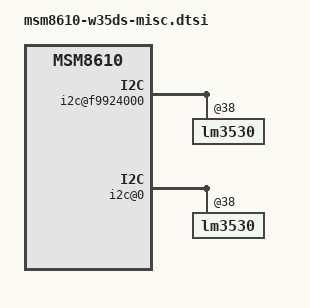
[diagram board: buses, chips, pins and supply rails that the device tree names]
/* Copyright (c) 2012, Code Aurora Forum. All rights reserved.
 *
 * This program is free software; you can redistribute it and/or modify
 * it under the terms of the GNU General Public License version 2 and
 * only version 2 as published by the Free Software Foundation.
 *
 * This program is distributed in the hope that it will be useful,
 * but WITHOUT ANY WARRANTY; without even the implied warranty of
 * MERCHANTABILITY or FITNESS FOR A PARTICULAR PURPOSE.  See the
 * GNU General Public License for more details.
 */

&soc {
	earjack-debugger {
		status = "disable";
	};

	i2c@f9924000 {
		rt8542@39 {
			status = "disable";
		};
        	lm3530@38 {
            		status = "ok";
            		revision = "rev_0";
        	};
		lp5521@32 {
			status = "disable";
			revision = "rev_0";
		};
	};

    i2c@0 {
        lm3530@38 {
            status = "ok";
            revision = "rev_a...";
            lm3530,max_current = <0x17>;
            lm3530,blmap = <
                0x01 0x01 0x01 0x01 0x01 0x01 0x01 0x01 0x01 0x01 /*09*/
                0x01 0x01 0x01 0x01 0x01 0x01 0x01 0x01 0x01 0x01 /*19*/
                0x01 0x01 0x01 0x01 0x01 0x01 0x02 0x02 0x02 0x02 /*29*/
                0x02 0x02 0x02 0x02 0x02 0x02 0x02 0x02 0x02 0x03 /*39*/
                0x03 0x03 0x03 0x03 0x03 0x03 0x03 0x03 0x03 0x03 /*49*/
                0x03 0x03 0x04 0x04 0x04 0x04 0x04 0x04 0x04 0x05 /*59*/
                0x05 0x05 0x05 0x05 0x05 0x05 0x05 0x06 0x06 0x06 /*69*/
                0x06 0x07 0x07 0x07 0x07 0x08 0x08 0x08 0x08 0x09 /*79*/
                0x09 0x09 0x09 0x0A 0x0A 0x0A 0x0B 0x0B 0x0B 0x0B /*89*/
                0x0B 0x0C 0x0C 0x0C 0x0C 0x0C 0x0D 0x0D 0x0D 0x0E /*99*/
                0x0E 0x0F 0x0F 0x10 0x10 0x10 0x11 0x11 0x12 0x12 /*109*/
                0x12 0x12 0x13 0x13 0x13 0x14 0x14 0x15 0x15 0x15 /*119*/
                0x16 0x16 0x16 0x17 0x17 0x18 0x18 0x19 0x19 0x1A /*129*/
                0x1B 0x1B 0x1C 0x1C 0x1C 0x1D 0x1D 0x1D 0x1D 0x1E /*139*/
                0x1E 0x1F 0x1F 0x1F 0x20 0x20 0x21 0x21 0x22 0x22 /*149*/
                0x22 0x22 0x23 0x23 0x24 0x24 0x25 0x26 0x26 0x26 /*159*/
                0x26 0x27 0x27 0x27 0x28 0x28 0x29 0x2A 0x2B 0x2B /*169*/
                0x2C 0x2D 0x2F 0x2F 0x30 0x31 0x31 0x32 0x33 0x34 /*179*/
                0x35 0x37 0x38 0x38 0x38 0x3A 0x3B 0x3C 0x3D 0x3E /*189*/
                0x3E 0x3F 0x40 0x41 0x41 0x41 0x42 0x43 0x43 0x44 /*199*/
                0x45 0x46 0x47 0x48 0x49 0x4B 0x4B 0x4B 0x4C 0x4D /*209*/
                0x4D 0x4E 0x4F 0x50 0x51 0x52 0x53 0x54 0x55 0x56 /*219*/
                0x56 0x56 0x58 0x59 0x5A 0x5B 0x5C 0x5D 0x5E 0x60 /*229*/
                0x62 0x63 0x63 0x63 0x64 0x65 0x66 0x68 0x6A 0x6B /*239*/
                0x6D 0x6F 0x70 0x70 0x70 0x71 0x73 0x75 0x76 0x77 /*249*/
                0x78 0x7A 0x7C 0x7D 0x7E 0x7F /*255*/>;
        };
        lp5521@32 {
            status = "disable";
            revision = "rev_a...";
        };
    };
};
